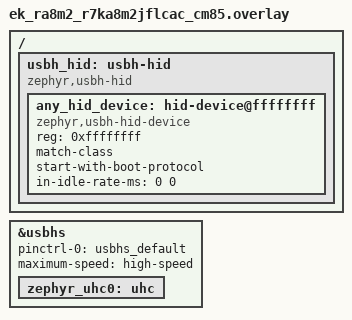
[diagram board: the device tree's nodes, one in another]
/*
 * Copyright (c) 2026 Renesas Electronics Corporation
 *
 * SPDX-License-Identifier: Apache-2.0
 */

/ {
	usbh_hid: usbh-hid {
		compatible = "zephyr,usbh-hid";

		#address-cells = <1>;
		#size-cells = <0>;

		any_hid_device: hid-device@ffffffff {
			compatible = "zephyr,usbh-hid-device";
			reg = <0xffffffff>;
			match-class;
			start-with-boot-protocol;
			in-idle-rate-ms = <0 0>;
			status = "okay";
		};
	};
};

&usbhs {
	pinctrl-0 = <&usbhs_default>;
	pinctrl-names = "default";
	maximum-speed = "high-speed";
	status = "okay";

	zephyr_uhc0: uhc {
		status = "okay";
	};
};
